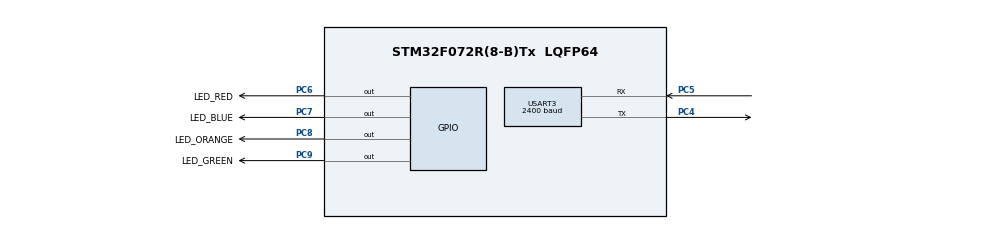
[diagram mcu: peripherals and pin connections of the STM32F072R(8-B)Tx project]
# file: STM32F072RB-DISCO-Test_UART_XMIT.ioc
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Mcu.Family=STM32F0
Mcu.Name=STM32F072R(8-B)Tx
Mcu.Package=LQFP64
PC14-OSC32_IN.Mode=LSE-External-Clock-Source
PC14-OSC32_IN.Signal=RCC_OSC32_IN
PC4.Mode=Asynchronous
PC4.Signal=USART3_TX
PC5.Mode=Asynchronous
PC5.Signal=USART3_RX
PC6.GPIO_Label=LED_RED
PC6.PinState=GPIO_PIN_SET
PC6.Signal=GPIO_Output
PC7.GPIO_Label=LED_BLUE
PC7.Signal=GPIO_Output
PC8.GPIO_Label=LED_ORANGE
PC8.Signal=GPIO_Output
PC9.GPIO_Label=LED_GREEN
PC9.Signal=GPIO_Output
PF0-OSC_IN.Mode=HSE-External-Clock-Source
PF0-OSC_IN.Signal=RCC_OSC_IN
ProjectManager.HeapSize=0x200
ProjectManager.StackSize=0x400
ProjectManager.TargetToolchain=STM32CubeIDE
USART3.BaudRate=2400
USART3.VirtualMode-Asynchronous=VM_ASYNC
board=custom

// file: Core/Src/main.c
/* USER CODE BEGIN Header */
/**
  ******************************************************************************
  * @file           : main.c
  * @brief          : Main program body
  ******************************************************************************
  * @attention
  *
  * <h2><center>&copy; Copyright (c) 2021 STMicroelectronics.
  * All rights reserved.</center></h2>
  *
  * This software component is licensed by ST under BSD 3-Clause license,
  * the "License"; You may not use this file except in compliance with the
  * License. You may obtain a copy of the License at:
  *                        opensource.org/licenses/BSD-3-Clause
  *
  ******************************************************************************
  */
/* USER CODE END Header */
#include "main.h"
#include <stdio.h>
#include <string.h>

UART_HandleTypeDef huart3;

/* USER CODE BEGIN PV */

/* Buffer used for transmission */
uint8_t aTxBuffer[32];
uint8_t const char_Line[] = "Line # ";
uint8_t const MYCR = 0x0D;
uint8_t const MYLF = '\n';
/* USER CODE END PV */

void SystemClock_Config(void);
static void MX_GPIO_Init(void);
static void MX_USART3_UART_Init(void);

int main(void)
{
  /* USER CODE BEGIN 1 */
unsigned int ui_line_count = 0;
int i_r = 0;
void * p_v = NULL;
  /* USER CODE END 1 */

  /* MCU Configuration--------------------------------------------------------*/

  /* Reset of all peripherals, Initializes the Flash interface and the Systick. */
  HAL_Init();

  /* Configure the system clock */
  SystemClock_Config();

  /* Initialize all configured peripherals */
  MX_GPIO_Init();
  MX_USART3_UART_Init();

  /* Infinite loop */
  /* USER CODE BEGIN WHILE */
  while (1)
  {
	  p_v = memset((void*)aTxBuffer,'\0',sizeof(aTxBuffer));
	  i_r = sprintf((char*)aTxBuffer,"%s %08x%c",char_Line,ui_line_count++,MYCR);
	  if(HAL_UART_Transmit(&huart3, (uint8_t *)aTxBuffer, i_r, 5000) != HAL_OK)
	  {
	    Error_Handler();
	  }
	  HAL_GPIO_TogglePin(GPIOC,LED_RED_Pin);
	  HAL_Delay((uint32_t)500);
	  HAL_GPIO_TogglePin(GPIOC,LED_RED_Pin);
/*	  HAL_GPIO_TogglePin(GPIOC,LED_GREEN_Pin); */
/*	  HAL_Delay((uint32_t)500); */
/*	  if(HAL_UART_Transmit(&huart3, (uint8_t *)aTxBuffer, sizeof(aTxBuffer), 50) != HAL_OK)
	  {
	    Error_Handler();
	  } */
/*	  HAL_GPIO_TogglePin(GPIOC,LED_GREEN_Pin); */
/*	  HAL_GPIO_TogglePin(GPIOC,LED_BLUE_Pin); */
/*	  HAL_Delay((uint32_t)500); */
/*	  HAL_GPIO_TogglePin(GPIOC,LED_BLUE_Pin); */
/*	  HAL_GPIO_TogglePin(GPIOC,LED_ORANGE_Pin); */
/*	  HAL_Delay((uint32_t)500); */
/*	  HAL_GPIO_TogglePin(GPIOC,LED_ORANGE_Pin); */
    /* USER CODE END WHILE */

  }
}

void SystemClock_Config(void)
{
  RCC_OscInitTypeDef RCC_OscInitStruct = {0};
  RCC_ClkInitTypeDef RCC_ClkInitStruct = {0};

  /** Initializes the RCC Oscillators according to the specified parameters
  * in the RCC_OscInitTypeDef structure.
  */
  RCC_OscInitStruct.OscillatorType = RCC_OSCILLATORTYPE_HSI;
  RCC_OscInitStruct.HSIState = RCC_HSI_ON;
  RCC_OscInitStruct.HSICalibrationValue = RCC_HSICALIBRATION_DEFAULT;
  RCC_OscInitStruct.PLL.PLLState = RCC_PLL_NONE;
  if (HAL_RCC_OscConfig(&RCC_OscInitStruct) != HAL_OK)
  {
    Error_Handler();
  }

  /** Initializes the CPU, AHB and APB buses clocks
  */
  RCC_ClkInitStruct.ClockType = RCC_CLOCKTYPE_HCLK|RCC_CLOCKTYPE_SYSCLK
                              |RCC_CLOCKTYPE_PCLK1;
  RCC_ClkInitStruct.SYSCLKSource = RCC_SYSCLKSOURCE_HSI;
  RCC_ClkInitStruct.AHBCLKDivider = RCC_SYSCLK_DIV1;
  RCC_ClkInitStruct.APB1CLKDivider = RCC_HCLK_DIV1;

  if (HAL_RCC_ClockConfig(&RCC_ClkInitStruct, FLASH_LATENCY_0) != HAL_OK)
  {
    Error_Handler();
  }
}

static void MX_USART3_UART_Init(void)
{

  huart3.Instance = USART3;
  huart3.Init.BaudRate = 2400;
  huart3.Init.WordLength = UART_WORDLENGTH_8B;
  huart3.Init.StopBits = UART_STOPBITS_1;
  huart3.Init.Parity = UART_PARITY_NONE;
  huart3.Init.Mode = UART_MODE_TX_RX;
  huart3.Init.HwFlowCtl = UART_HWCONTROL_NONE;
  huart3.Init.OverSampling = UART_OVERSAMPLING_16;
  huart3.Init.OneBitSampling = UART_ONE_BIT_SAMPLE_DISABLE;
  huart3.AdvancedInit.AdvFeatureInit = UART_ADVFEATURE_NO_INIT;
  if (HAL_UART_Init(&huart3) != HAL_OK)
  {
    Error_Handler();
  }

}

static void MX_GPIO_Init(void)
{
  GPIO_InitTypeDef GPIO_InitStruct = {0};

  /* GPIO Ports Clock Enable */
  __HAL_RCC_GPIOC_CLK_ENABLE();
  __HAL_RCC_GPIOF_CLK_ENABLE();

  /*Configure GPIO pin Output Level */
  HAL_GPIO_WritePin(LED_RED_GPIO_Port, LED_RED_Pin, GPIO_PIN_SET);

  /*Configure GPIO pin Output Level */
  HAL_GPIO_WritePin(GPIOC, LED_BLUE_Pin|LED_ORANGE_Pin|LED_GREEN_Pin, GPIO_PIN_RESET);

  /*Configure GPIO pins : LED_RED_Pin LED_BLUE_Pin LED_ORANGE_Pin LED_GREEN_Pin */
  GPIO_InitStruct.Pin = LED_RED_Pin|LED_BLUE_Pin|LED_ORANGE_Pin|LED_GREEN_Pin;
  GPIO_InitStruct.Mode = GPIO_MODE_OUTPUT_PP;
  GPIO_InitStruct.Pull = GPIO_NOPULL;
  GPIO_InitStruct.Speed = GPIO_SPEED_FREQ_LOW;
  HAL_GPIO_Init(GPIOC, &GPIO_InitStruct);

}

void Error_Handler(void)
{
  __disable_irq();
  while (1)
  {
  }
}
